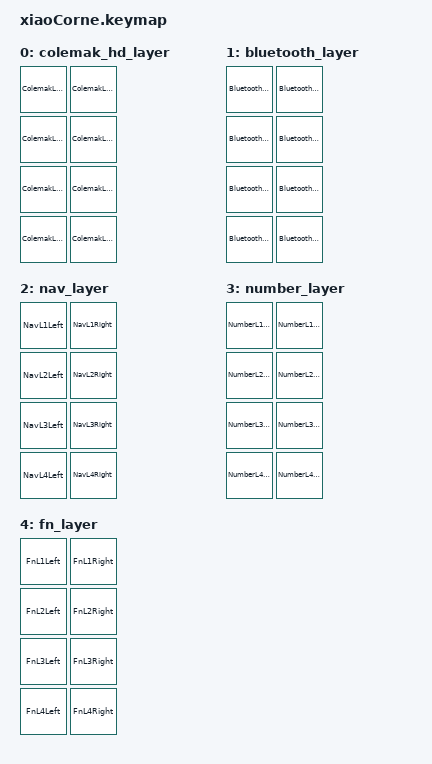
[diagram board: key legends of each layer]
#include <behaviors.dtsi>
#include <dt-bindings/zmk/keys.h>
#include <dt-bindings/zmk/bt.h>

#include "modifiers.h"
#include "bluetooth_layer.h"
#include "colemak_custom_layer.h"
#include "fn_layer.h"
#include "nav_layer.h"
#include "number_layer.h"

&caps_word {
	continue-list = <UNDERSCORE BACKSPACE DELETE>;
};

/ {
	combos {
		compatible = "zmk,combos";
		combo_caps {
			timeout-ms = <50>;
			key-positions = <15 20>;
			bindings = <&caps_word>;
			layers = <0>;
		};

		// (
		combo_LPAR {
			timeout-ms = <50>;
			key-positions = <15 16>;
			bindings = <&kp LPAR>;
			layers = <0>;
		};

		// )
		combo_RPAR {
			timeout-ms = <50>;
			key-positions = <19 20>;
			bindings = <&kp RPAR>;
			layers = <0>;
		};

		// [
		combo_LBKT {
			timeout-ms = <50>;
			key-positions = <3 4>;
			bindings = <&kp LBKT>;
			layers = <0>;
		};

		// ]
		combo_RBKT {
			timeout-ms = <50>;
			key-positions = <7 8>;
			bindings = <&kp RBKT>;
			layers = <0>;
		};

		// {
		combo_LBRC {
			timeout-ms = <50>;
			key-positions = <27 28>;
			bindings = <&kp LBRC>;
			layers = <0>;
		};

		// }
		combo_RBRC {
			timeout-ms = <50>;
			key-positions = <31 32>;
			bindings = <&kp RBRC>;
			layers = <0>;
		};

		// "
		combo_DQT {
			timeout-ms = <50>;
			key-positions = <14 15>;
			bindings = <&kp DQT>;
			layers = <0>;
		};

		// '
		combo_SQT {
			timeout-ms = <50>;
			key-positions = <2 3>;
			bindings = <&kp SQT>;
			layers = <0>;
		};

		// `
		combo_GRAVE {
			timeout-ms = <50>;
			key-positions = <26 27>;
			bindings = <&kp GRAVE>;
			layers = <0>;
		};
	};

	keymap {
		compatible = "zmk,keymap";
		colemak_hd_layer {
			bindings = <
				ColemakL1Left  ColemakL1Right
				ColemakL2Left  ColemakL2Right
				ColemakL3Left  ColemakL3Right
				ColemakL4Left  ColemakL4Right
			>;
		};

		bluetooth_layer {
			bindings = <
				BluetoothL1Left  BluetoothL1Right
				BluetoothL2Left  BluetoothL2Right
				BluetoothL3Left  BluetoothL3Right
				BluetoothL4Left  BluetoothL4Right
			>;
		};

		nav_layer {
			bindings = <
				NavL1Left  NavL1Right
				NavL2Left  NavL2Right
				NavL3Left  NavL3Right
				NavL4Left  NavL4Right
			>;
		};

		number_layer {
			bindings = <
				NumberL1Left  NumberL1Right
				NumberL2Left  NumberL2Right
				NumberL3Left  NumberL3Right
				NumberL4Left  NumberL4Right
			>;
		};

		fn_layer {
			bindings = <
				FnL1Left  FnL1Right
				FnL2Left  FnL2Right
				FnL3Left  FnL3Right
				FnL4Left  FnL4Right
			>;
		};
	};
};
